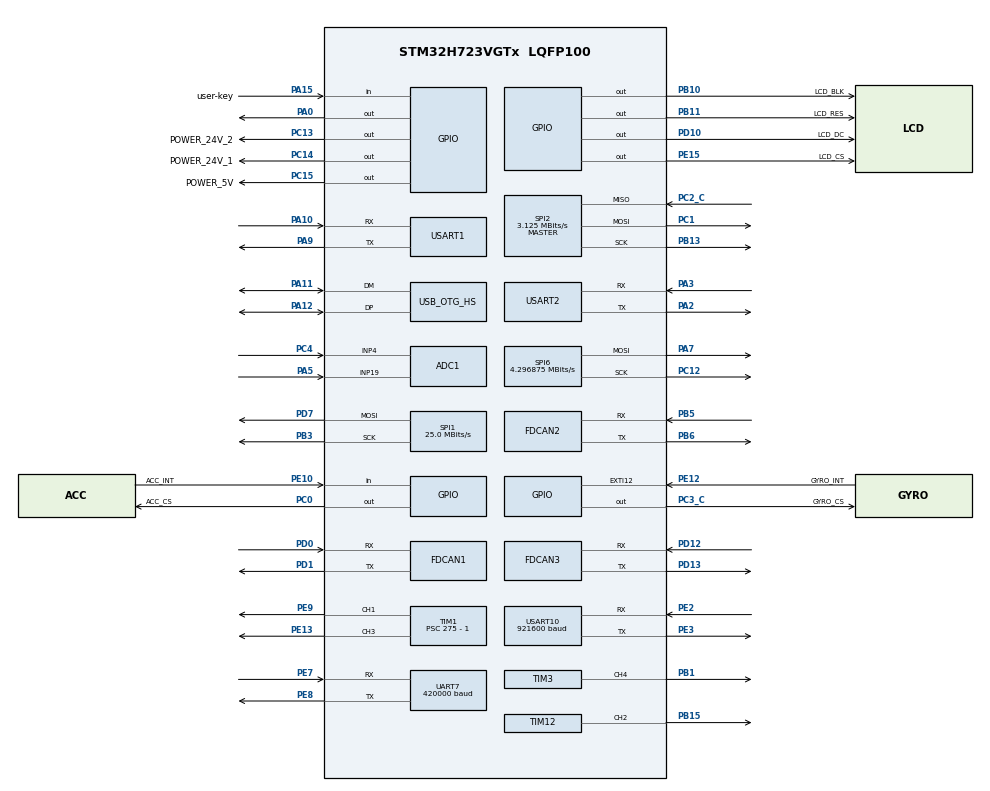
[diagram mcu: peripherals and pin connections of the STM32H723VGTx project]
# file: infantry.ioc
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ADC1.Channel-0\#ChannelRegularConversion=ADC_CHANNEL_4
ADC1.Channel-1\#ChannelRegularConversion=ADC_CHANNEL_19
ADC1.ClockPrescaler=ADC_CLOCK_ASYNC_DIV64
ADC1.ContinuousConvMode=ENABLE
ADC1.ConversionDataManagement=ADC_CONVERSIONDATA_DMA_CIRCULAR
ADC1.NbrOfConversion=2
ADC1.NbrOfConversionFlag=1
ADC1.OffsetNumber-0\#ChannelRegularConversion=ADC_OFFSET_NONE
ADC1.OffsetNumber-1\#ChannelRegularConversion=ADC_OFFSET_NONE
ADC1.OffsetSignedSaturation-0\#ChannelRegularConversion=DISABLE
ADC1.OffsetSignedSaturation-1\#ChannelRegularConversion=DISABLE
ADC1.Rank-0\#ChannelRegularConversion=1
ADC1.Rank-1\#ChannelRegularConversion=2
ADC1.Ratio=1
ADC1.SamplingTime-0\#ChannelRegularConversion=ADC_SAMPLETIME_32CYCLES_5
ADC1.SamplingTime-1\#ChannelRegularConversion=ADC_SAMPLETIME_32CYCLES_5
ADC1.master=1
CORTEX_M7.AccessPermission_Spec=MPU_REGION_FULL_ACCESS
CORTEX_M7.BaseAddress_Spec=0x24000000
CORTEX_M7.CPU_DCache=Enabled
CORTEX_M7.CPU_ICache=Enabled
CORTEX_M7.DisableExec_Spec=MPU_INSTRUCTION_ACCESS_ENABLE
CORTEX_M7.IsBufferable_Spec=MPU_ACCESS_NOT_BUFFERABLE
CORTEX_M7.IsCacheable_Spec=MPU_ACCESS_NOT_CACHEABLE
CORTEX_M7.IsShareable_Spec=MPU_ACCESS_NOT_SHAREABLE
CORTEX_M7.MPU_Control=MPU_HFNMI_PRIVDEF
CORTEX_M7.Size_Spec=MPU_REGION_SIZE_512KB
CORTEX_M7.SubRegionDisable_Spec=0x0
CORTEX_M7.TypeExtField_Spec=MPU_TEX_LEVEL1
CORTEX_M7.default_mode_Activation=1
Dma.ADC1.8.Direction=DMA_PERIPH_TO_MEMORY
Dma.ADC1.8.EventEnable=DISABLE
Dma.ADC1.8.FIFOMode=DMA_FIFOMODE_DISABLE
Dma.ADC1.8.Instance=DMA2_Stream0
Dma.ADC1.8.MemDataAlignment=DMA_MDATAALIGN_HALFWORD
Dma.ADC1.8.MemInc=DMA_MINC_ENABLE
Dma.ADC1.8.Mode=DMA_CIRCULAR
Dma.ADC1.8.PeriphDataAlignment=DMA_PDATAALIGN_HALFWORD
Dma.ADC1.8.PeriphInc=DMA_PINC_DISABLE
Dma.ADC1.8.Polarity=HAL_DMAMUX_REQ_GEN_RISING
Dma.ADC1.8.Priority=DMA_PRIORITY_LOW
Dma.ADC1.8.RequestNumber=1
Dma.ADC1.8.SignalID=NONE
Dma.ADC1.8.SyncEnable=DISABLE
Dma.ADC1.8.SyncPolarity=HAL_DMAMUX_SYNC_NO_EVENT
Dma.ADC1.8.SyncRequestNumber=1
Dma.ADC1.8.SyncSignalID=NONE
Dma.Request0=SPI2_RX
Dma.Request1=SPI2_TX
Dma.Request10=USART1_TX
Dma.Request2=USART2_RX
Dma.Request3=USART2_TX
Dma.Request4=USART10_RX
Dma.Request5=USART10_TX
Dma.Request6=UART7_RX
Dma.Request7=UART7_TX
Dma.Request8=ADC1
Dma.Request9=USART1_RX
Dma.SPI2_RX.0.Direction=DMA_PERIPH_TO_MEMORY
Dma.SPI2_RX.0.EventEnable=DISABLE
Dma.SPI2_RX.0.FIFOMode=DMA_FIFOMODE_DISABLE
Dma.SPI2_RX.0.Instance=DMA1_Stream0
Dma.SPI2_RX.0.MemDataAlignment=DMA_MDATAALIGN_BYTE
Dma.SPI2_RX.0.MemInc=DMA_MINC_ENABLE
Dma.SPI2_RX.0.Mode=DMA_NORMAL
Dma.SPI2_RX.0.PeriphDataAlignment=DMA_PDATAALIGN_BYTE
Dma.SPI2_RX.0.PeriphInc=DMA_PINC_DISABLE
Dma.SPI2_RX.0.Polarity=HAL_DMAMUX_REQ_GEN_RISING
Dma.SPI2_RX.0.Priority=DMA_PRIORITY_VERY_HIGH
Dma.SPI2_RX.0.RequestNumber=1
Dma.SPI2_RX.0.SignalID=NONE
Dma.SPI2_RX.0.SyncEnable=DISABLE
Dma.SPI2_RX.0.SyncPolarity=HAL_DMAMUX_SYNC_NO_EVENT
Dma.SPI2_RX.0.SyncRequestNumber=1
Dma.SPI2_RX.0.SyncSignalID=NONE
Dma.SPI2_TX.1.Direction=DMA_MEMORY_TO_PERIPH
Dma.SPI2_TX.1.EventEnable=DISABLE
Dma.SPI2_TX.1.FIFOMode=DMA_FIFOMODE_DISABLE
Dma.SPI2_TX.1.Instance=DMA1_Stream1
Dma.SPI2_TX.1.MemDataAlignment=DMA_MDATAALIGN_BYTE
Dma.SPI2_TX.1.MemInc=DMA_MINC_ENABLE
Dma.SPI2_TX.1.Mode=DMA_NORMAL
Dma.SPI2_TX.1.PeriphDataAlignment=DMA_PDATAALIGN_BYTE
Dma.SPI2_TX.1.PeriphInc=DMA_PINC_DISABLE
Dma.SPI2_TX.1.Polarity=HAL_DMAMUX_REQ_GEN_RISING
Dma.SPI2_TX.1.Priority=DMA_PRIORITY_HIGH
Dma.SPI2_TX.1.RequestNumber=1
Dma.SPI2_TX.1.SignalID=NONE
Dma.SPI2_TX.1.SyncEnable=DISABLE
Dma.SPI2_TX.1.SyncPolarity=HAL_DMAMUX_SYNC_NO_EVENT
Dma.SPI2_TX.1.SyncRequestNumber=1
Dma.SPI2_TX.1.SyncSignalID=NONE
Dma.UART7_RX.6.Direction=DMA_PERIPH_TO_MEMORY
Dma.UART7_RX.6.EventEnable=DISABLE
Dma.UART7_RX.6.FIFOMode=DMA_FIFOMODE_DISABLE
Dma.UART7_RX.6.Instance=DMA1_Stream4
Dma.UART7_RX.6.MemDataAlignment=DMA_MDATAALIGN_BYTE
Dma.UART7_RX.6.MemInc=DMA_MINC_ENABLE
Dma.UART7_RX.6.Mode=DMA_NORMAL
Dma.UART7_RX.6.PeriphDataAlignment=DMA_PDATAALIGN_BYTE
Dma.UART7_RX.6.PeriphInc=DMA_PINC_DISABLE
Dma.UART7_RX.6.Polarity=HAL_DMAMUX_REQ_GEN_RISING
Dma.UART7_RX.6.Priority=DMA_PRIORITY_VERY_HIGH
Dma.UART7_RX.6.RequestNumber=1
Dma.UART7_RX.6.SignalID=NONE
Dma.UART7_RX.6.SyncEnable=DISABLE
Dma.UART7_RX.6.SyncPolarity=HAL_DMAMUX_SYNC_NO_EVENT
Dma.UART7_RX.6.SyncRequestNumber=1
Dma.UART7_RX.6.SyncSignalID=NONE
Dma.UART7_TX.7.Direction=DMA_MEMORY_TO_PERIPH
Dma.UART7_TX.7.EventEnable=DISABLE
Dma.UART7_TX.7.FIFOMode=DMA_FIFOMODE_DISABLE
Dma.UART7_TX.7.Instance=DMA1_Stream5
Dma.UART7_TX.7.MemDataAlignment=DMA_MDATAALIGN_BYTE
Dma.UART7_TX.7.MemInc=DMA_MINC_ENABLE
Dma.UART7_TX.7.Mode=DMA_NORMAL
Dma.UART7_TX.7.PeriphDataAlignment=DMA_PDATAALIGN_BYTE
Dma.UART7_TX.7.PeriphInc=DMA_PINC_DISABLE
Dma.UART7_TX.7.Polarity=HAL_DMAMUX_REQ_GEN_RISING
Dma.UART7_TX.7.Priority=DMA_PRIORITY_LOW
Dma.UART7_TX.7.RequestNumber=1
Dma.UART7_TX.7.SignalID=NONE
Dma.UART7_TX.7.SyncEnable=DISABLE
Dma.UART7_TX.7.SyncPolarity=HAL_DMAMUX_SYNC_NO_EVENT
Dma.UART7_TX.7.SyncRequestNumber=1
Dma.UART7_TX.7.SyncSignalID=NONE
Dma.USART10_RX.4.Direction=DMA_PERIPH_TO_MEMORY
Dma.USART10_RX.4.EventEnable=DISABLE
Dma.USART10_RX.4.FIFOMode=DMA_FIFOMODE_DISABLE
Dma.USART10_RX.4.Instance=DMA1_Stream6
Dma.USART10_RX.4.MemDataAlignment=DMA_MDATAALIGN_BYTE
Dma.USART10_RX.4.MemInc=DMA_MINC_ENABLE
Dma.USART10_RX.4.Mode=DMA_NORMAL
Dma.USART10_RX.4.PeriphDataAlignment=DMA_PDATAALIGN_BYTE
Dma.USART10_RX.4.PeriphInc=DMA_PINC_DISABLE
Dma.USART10_RX.4.Polarity=HAL_DMAMUX_REQ_GEN_RISING
Dma.USART10_RX.4.Priority=DMA_PRIORITY_HIGH
Dma.USART10_RX.4.RequestNumber=1
Dma.USART10_RX.4.SignalID=NONE
Dma.USART10_RX.4.SyncEnable=DISABLE
Dma.USART10_RX.4.SyncPolarity=HAL_DMAMUX_SYNC_NO_EVENT
Dma.USART10_RX.4.SyncRequestNumber=1
Dma.USART10_RX.4.SyncSignalID=NONE
Dma.USART10_TX.5.Direction=DMA_MEMORY_TO_PERIPH
Dma.USART10_TX.5.EventEnable=DISABLE
Dma.USART10_TX.5.FIFOMode=DMA_FIFOMODE_DISABLE
Dma.USART10_TX.5.Instance=DMA1_Stream7
Dma.USART10_TX.5.MemDataAlignment=DMA_MDATAALIGN_BYTE
Dma.USART10_TX.5.MemInc=DMA_MINC_ENABLE
Dma.USART10_TX.5.Mode=DMA_NORMAL
Dma.USART10_TX.5.PeriphDataAlignment=DMA_PDATAALIGN_BYTE
Dma.USART10_TX.5.PeriphInc=DMA_PINC_DISABLE
Dma.USART10_TX.5.Polarity=HAL_DMAMUX_REQ_GEN_RISING
Dma.USART10_TX.5.Priority=DMA_PRIORITY_HIGH
Dma.USART10_TX.5.RequestNumber=1
Dma.USART10_TX.5.SignalID=NONE
Dma.USART10_TX.5.SyncEnable=DISABLE
Dma.USART10_TX.5.SyncPolarity=HAL_DMAMUX_SYNC_NO_EVENT
Dma.USART10_TX.5.SyncRequestNumber=1
Dma.USART10_TX.5.SyncSignalID=NONE
Dma.USART1_RX.9.Direction=DMA_PERIPH_TO_MEMORY
Dma.USART1_RX.9.EventEnable=DISABLE
Dma.USART1_RX.9.FIFOMode=DMA_FIFOMODE_DISABLE
Dma.USART1_RX.9.Instance=DMA2_Stream1
Dma.USART1_RX.9.MemDataAlignment=DMA_MDATAALIGN_BYTE
Dma.USART1_RX.9.MemInc=DMA_MINC_ENABLE
Dma.USART1_RX.9.Mode=DMA_NORMAL
Dma.USART1_RX.9.PeriphDataAlignment=DMA_PDATAALIGN_BYTE
Dma.USART1_RX.9.PeriphInc=DMA_PINC_DISABLE
Dma.USART1_RX.9.Polarity=HAL_DMAMUX_REQ_GEN_RISING
Dma.USART1_RX.9.Priority=DMA_PRIORITY_LOW
Dma.USART1_RX.9.RequestNumber=1
Dma.USART1_RX.9.SignalID=NONE
Dma.USART1_RX.9.SyncEnable=DISABLE
Dma.USART1_RX.9.SyncPolarity=HAL_DMAMUX_SYNC_NO_EVENT
Dma.USART1_RX.9.SyncRequestNumber=1
Dma.USART1_RX.9.SyncSignalID=NONE
Dma.USART1_TX.10.Direction=DMA_MEMORY_TO_PERIPH
Dma.USART1_TX.10.EventEnable=DISABLE
Dma.USART1_TX.10.FIFOMode=DMA_FIFOMODE_DISABLE
Dma.USART1_TX.10.Instance=DMA2_Stream2
Dma.USART1_TX.10.MemDataAlignment=DMA_MDATAALIGN_BYTE
Dma.USART1_TX.10.MemInc=DMA_MINC_ENABLE
Dma.USART1_TX.10.Mode=DMA_NORMAL
Dma.USART1_TX.10.PeriphDataAlignment=DMA_PDATAALIGN_BYTE
Dma.USART1_TX.10.PeriphInc=DMA_PINC_DISABLE
Dma.USART1_TX.10.Polarity=HAL_DMAMUX_REQ_GEN_RISING
Dma.USART1_TX.10.Priority=DMA_PRIORITY_HIGH
Dma.USART1_TX.10.RequestNumber=1
Dma.USART1_TX.10.SignalID=NONE
Dma.USART1_TX.10.SyncEnable=DISABLE
Dma.USART1_TX.10.SyncPolarity=HAL_DMAMUX_SYNC_NO_EVENT
Dma.USART1_TX.10.SyncRequestNumber=1
Dma.USART1_TX.10.SyncSignalID=NONE
Dma.USART2_RX.2.Direction=DMA_PERIPH_TO_MEMORY
Dma.USART2_RX.2.EventEnable=DISABLE
Dma.USART2_RX.2.FIFOMode=DMA_FIFOMODE_DISABLE
Dma.USART2_RX.2.Instance=DMA1_Stream2
Dma.USART2_RX.2.MemDataAlignment=DMA_MDATAALIGN_BYTE
Dma.USART2_RX.2.MemInc=DMA_MINC_ENABLE
Dma.USART2_RX.2.Mode=DMA_NORMAL
Dma.USART2_RX.2.PeriphDataAlignment=DMA_PDATAALIGN_BYTE
Dma.USART2_RX.2.PeriphInc=DMA_PINC_DISABLE
Dma.USART2_RX.2.Polarity=HAL_DMAMUX_REQ_GEN_RISING
Dma.USART2_RX.2.Priority=DMA_PRIORITY_LOW
Dma.USART2_RX.2.RequestNumber=1
Dma.USART2_RX.2.SignalID=NONE
Dma.USART2_RX.2.SyncEnable=DISABLE
Dma.USART2_RX.2.SyncPolarity=HAL_DMAMUX_SYNC_NO_EVENT
Dma.USART2_RX.2.SyncRequestNumber=1
Dma.USART2_RX.2.SyncSignalID=NONE
Dma.USART2_TX.3.Direction=DMA_MEMORY_TO_PERIPH
Dma.USART2_TX.3.EventEnable=DISABLE
Dma.USART2_TX.3.FIFOMode=DMA_FIFOMODE_DISABLE
Dma.USART2_TX.3.Instance=DMA1_Stream3
Dma.USART2_TX.3.MemDataAlignment=DMA_MDATAALIGN_BYTE
Dma.USART2_TX.3.MemInc=DMA_MINC_ENABLE
Dma.USART2_TX.3.Mode=DMA_NORMAL
Dma.USART2_TX.3.PeriphDataAlignment=DMA_PDATAALIGN_BYTE
Dma.USART2_TX.3.PeriphInc=DMA_PINC_DISABLE
Dma.USART2_TX.3.Polarity=HAL_DMAMUX_REQ_GEN_RISING
Dma.USART2_TX.3.Priority=DMA_PRIORITY_LOW
Dma.USART2_TX.3.RequestNumber=1
Dma.USART2_TX.3.SignalID=NONE
Dma.USART2_TX.3.SyncEnable=DISABLE
Dma.USART2_TX.3.SyncPolarity=HAL_DMAMUX_SYNC_NO_EVENT
Dma.USART2_TX.3.SyncRequestNumber=1
Dma.USART2_TX.3.SyncSignalID=NONE
FDCAN1.AutoRetransmission=ENABLE
FDCAN1.CalculateBaudRateNominal=1000000
FDCAN1.CalculateTimeBitNominal=1000
FDCAN1.CalculateTimeQuantumNominal=50.0
FDCAN1.DataPrescaler=5
FDCAN1.DataSyncJumpWidth=5
FDCAN1.DataTimeSeg1=14
FDCAN1.DataTimeSeg2=5
FDCAN1.NominalPrescaler=5
FDCAN1.NominalSyncJumpWidth=5
FDCAN1.NominalTimeSeg1=14
FDCAN1.NominalTimeSeg2=5
FDCAN1.ProtocolException=ENABLE
FDCAN1.RxFifo0ElmtsNbr=8
FDCAN1.StdFiltersNbr=1
FDCAN1.TxFifoQueueElmtsNbr=8
FDCAN2.AutoRetransmission=ENABLE
FDCAN2.CalculateBaudRateNominal=1000000
FDCAN2.CalculateTimeBitNominal=1000
FDCAN2.CalculateTimeQuantumNominal=50.0
FDCAN2.DataSyncJumpWidth=5
FDCAN2.DataTimeSeg1=14
FDCAN2.DataTimeSeg2=5
FDCAN2.MessageRAMOffset=853
FDCAN2.NominalPrescaler=5
FDCAN2.NominalSyncJumpWidth=5
FDCAN2.NominalTimeSeg1=14
FDCAN2.NominalTimeSeg2=5
FDCAN2.ProtocolException=ENABLE
FDCAN2.RxFifo1ElmtsNbr=8
FDCAN2.StdFiltersNbr=1
FDCAN2.TxFifoQueueElmtsNbr=8
FDCAN3.AutoRetransmission=ENABLE
FDCAN3.CalculateBaudRateNominal=1000000
FDCAN3.CalculateTimeBitNominal=1000
FDCAN3.CalculateTimeQuantumNominal=50.0
FDCAN3.DataPrescaler=5
FDCAN3.DataSyncJumpWidth=5
FDCAN3.DataTimeSeg1=14
FDCAN3.DataTimeSeg2=5
FDCAN3.MessageRAMOffset=1706
FDCAN3.NominalPrescaler=5
FDCAN3.NominalSyncJumpWidth=5
FDCAN3.NominalTimeSeg1=14
FDCAN3.NominalTimeSeg2=5
FDCAN3.ProtocolException=ENABLE
FDCAN3.RxFifo0ElmtsNbr=8
FDCAN3.StdFiltersNbr=1
FDCAN3.TxFifoQueueElmtsNbr=8
FREERTOS.Tasks01=defaultTask,24,256,StartDefaultTask,Default,NULL,Static,defaultTaskBuffer,defaultTaskControlBlock;test,8,128,test_task,As weak,NULL,Static,testBuffer,testControlBlock;remote_control,24,512,remote_control_task,As weak,NULL,Static,remote_controlBuffer,remote_controlControlBlock;decision_center,24,1024,decision_center_task,As weak,NULL,Static,decision_centerBuffer,decision_centerControlBlock;safe_daemon,24,256,safe_daemon_task,As weak,NULL,Static,safe_daemonBuffer,safe_daemonControlBlock;ins_task_rtos,40,1024,imu_task,As weak,NULL,Static,ins_task_rtosBuffer,ins_task_rtosControlBlock;chassis,24,1024,chassis_task,As weak,NULL,Static,chassisBuffer,chassisControlBlock
FREERTOS.configCHECK_FOR_STACK_OVERFLOW=0
FREERTOS.configENABLE_FPU=1
FREERTOS.configTOTAL_HEAP_SIZE=15360
Mcu.Family=STM32H7
Mcu.Name=STM32H723VGTx
Mcu.Package=LQFP100
NVIC.DMA1_Stream0_IRQn=true\:5\:0\:false\:false\:true\:true\:false\:true\:true
NVIC.DMA1_Stream1_IRQn=true\:5\:0\:false\:false\:true\:true\:false\:true\:true
NVIC.DMA1_Stream2_IRQn=true\:5\:0\:false\:false\:true\:true\:false\:true\:true
NVIC.DMA1_Stream3_IRQn=true\:5\:0\:false\:false\:true\:true\:false\:true\:true
NVIC.DMA1_Stream4_IRQn=true\:5\:0\:false\:false\:true\:true\:false\:true\:true
NVIC.DMA1_Stream5_IRQn=true\:5\:0\:false\:false\:true\:true\:false\:true\:true
NVIC.DMA1_Stream6_IRQn=true\:5\:0\:false\:false\:true\:true\:false\:true\:true
NVIC.DMA1_Stream7_IRQn=true\:5\:0\:false\:false\:true\:true\:false\:true\:true
NVIC.DMA2_Stream0_IRQn=true\:5\:0\:false\:false\:true\:true\:false\:true\:true
NVIC.DMA2_Stream1_IRQn=true\:5\:0\:false\:false\:true\:true\:false\:true\:true
NVIC.DMA2_Stream2_IRQn=true\:5\:0\:false\:false\:true\:true\:false\:true\:true
NVIC.EXTI15_10_IRQn=true\:5\:0\:false\:false\:true\:true\:true\:true\:true
NVIC.FDCAN1_IT0_IRQn=true\:5\:0\:false\:false\:true\:true\:true\:true\:true
NVIC.FDCAN1_IT1_IRQn=true\:5\:0\:false\:false\:true\:true\:true\:true\:true
NVIC.FDCAN2_IT0_IRQn=true\:5\:0\:false\:false\:true\:true\:true\:true\:true
NVIC.FDCAN2_IT1_IRQn=true\:5\:0\:false\:false\:true\:true\:true\:true\:true
NVIC.FDCAN3_IT0_IRQn=true\:5\:0\:false\:false\:true\:true\:true\:true\:true
NVIC.FDCAN3_IT1_IRQn=true\:5\:0\:false\:false\:true\:true\:true\:true\:true
NVIC.OTG_HS_IRQn=true\:5\:0\:false\:false\:true\:true\:true\:true\:true
NVIC.PriorityGroup=NVIC_PRIORITYGROUP_4
NVIC.SPI2_IRQn=true\:5\:0\:false\:false\:true\:true\:false\:true\:true
NVIC.TIM2_IRQn=true\:15\:0\:false\:false\:true\:false\:false\:true\:true
NVIC.TimeBase=TIM2_IRQn
NVIC.TimeBaseIP=TIM2
NVIC.UART7_IRQn=true\:5\:0\:false\:false\:true\:true\:true\:true\:true
NVIC.USART10_IRQn=true\:5\:0\:false\:false\:true\:true\:true\:true\:true
NVIC.USART1_IRQn=true\:5\:0\:false\:false\:true\:true\:true\:true\:true
NVIC.USART2_IRQn=true\:5\:0\:false\:false\:true\:true\:true\:true\:true
PA0.GPIO_Speed=GPIO_SPEED_FREQ_VERY_HIGH
PA0.Signal=GPIO_Output
PA10.Mode=Asynchronous
PA10.Signal=USART1_RX
PA11.Mode=Device_Only_FS
PA11.Signal=USB_OTG_HS_DM
PA12.Mode=Device_Only_FS
PA12.Signal=USB_OTG_HS_DP
PA13(JTMS/SWDIO).Mode=Serial_Wire
PA13(JTMS/SWDIO).Signal=DEBUG_JTMS-SWDIO
PA14(JTCK/SWCLK).Mode=Serial_Wire
PA14(JTCK/SWCLK).Signal=DEBUG_JTCK-SWCLK
PA15(JTDI).GPIO_Label=user-key
PA15(JTDI).GPIO_PuPd=GPIO_PULLUP
PA15(JTDI).Signal=GPIO_Input
PA2.Mode=Asynchronous
PA2.Signal=USART2_TX
PA3.Mode=Asynchronous
PA3.Signal=USART2_RX
PA5.Signal=ADCx_INP19
PA7.GPIO_Speed=GPIO_SPEED_FREQ_VERY_HIGH
PA7.Mode=TX_Only_Simplex_Unidirect_Master
PA7.Signal=SPI6_MOSI
PA9.Mode=Asynchronous
PA9.Signal=USART1_TX
PB1.Signal=S_TIM3_CH4
PB10.GPIO_Label=LCD_BLK
PB10.Signal=GPIO_Output
PB11.GPIO_Label=LCD_RES
PB11.Signal=GPIO_Output
PB13.GPIO_Speed=GPIO_SPEED_FREQ_VERY_HIGH
PB13.Mode=Full_Duplex_Master
PB13.Signal=SPI2_SCK
PB15.Signal=S_TIM12_CH2
PB3(JTDO/TRACESWO).Mode=TX_Only_Simplex_Unidirect_Master
PB3(JTDO/TRACESWO).Signal=SPI1_SCK
PB5.Mode=FDCAN_Activate
PB5.Signal=FDCAN2_RX
PB6.Mode=FDCAN_Activate
PB6.Signal=FDCAN2_TX
PC0.GPIO_Label=ACC_CS
PC0.GPIO_Speed=GPIO_SPEED_FREQ_VERY_HIGH
PC0.PinState=GPIO_PIN_SET
PC0.Signal=GPIO_Output
PC1.GPIO_Speed=GPIO_SPEED_FREQ_VERY_HIGH
PC1.Mode=Full_Duplex_Master
PC1.Signal=SPI2_MOSI
PC12.GPIO_Speed=GPIO_SPEED_FREQ_VERY_HIGH
PC12.Mode=TX_Only_Simplex_Unidirect_Master
PC12.Signal=SPI6_SCK
PC13.GPIO_Label=POWER_24V_2
PC13.PinState=GPIO_PIN_SET
PC13.Signal=GPIO_Output
PC14-OSC32_IN.GPIO_Label=POWER_24V_1
PC14-OSC32_IN.PinState=GPIO_PIN_SET
PC14-OSC32_IN.Signal=GPIO_Output
PC15-OSC32_OUT.GPIO_Label=POWER_5V
PC15-OSC32_OUT.PinState=GPIO_PIN_SET
PC15-OSC32_OUT.Signal=GPIO_Output
PC2_C.GPIO_Speed=GPIO_SPEED_FREQ_VERY_HIGH
PC2_C.Mode=Full_Duplex_Master
PC2_C.Signal=SPI2_MISO
PC3_C.GPIO_Label=GYRO_CS
PC3_C.GPIO_Speed=GPIO_SPEED_FREQ_VERY_HIGH
PC3_C.PinState=GPIO_PIN_SET
PC3_C.Signal=GPIO_Output
PC4.Signal=ADCx_INP4
PD0.Mode=FDCAN_Activate
PD0.Signal=FDCAN1_RX
PD1.Mode=FDCAN_Activate
PD1.Signal=FDCAN1_TX
PD10.GPIO_Label=LCD_DC
PD10.Signal=GPIO_Output
PD12.Mode=FDCAN_Activate
PD12.Signal=FDCAN3_RX
PD13.Mode=FDCAN_Activate
PD13.Signal=FDCAN3_TX
PD7.Mode=TX_Only_Simplex_Unidirect_Master
PD7.Signal=SPI1_MOSI
PE10.GPIO_Label=ACC_INT
PE10.Signal=GPIO_Input
PE12.GPIO_Label=GYRO_INT
PE12.GPIO_ModeDefaultEXTI=GPIO_MODE_IT_FALLING
PE12.Signal=GPXTI12
PE13.Signal=S_TIM1_CH3
PE15.GPIO_Label=LCD_CS
PE15.Signal=GPIO_Output
PE2.GPIO_Speed=GPIO_SPEED_FREQ_LOW
PE2.Mode=Asynchronous
PE2.Signal=USART10_RX
PE3.GPIO_Speed=GPIO_SPEED_FREQ_LOW
PE3.Mode=Asynchronous
PE3.Signal=USART10_TX
PE7.Mode=Asynchronous
PE7.Signal=UART7_RX
PE8.Mode=Asynchronous
PE8.Signal=UART7_TX
PE9.Signal=S_TIM1_CH1
PH0-OSC_IN.Mode=HSE-External-Oscillator
PH0-OSC_IN.Signal=RCC_OSC_IN
PH1-OSC_OUT.Mode=HSE-External-Oscillator
PH1-OSC_OUT.Signal=RCC_OSC_OUT
ProjectManager.HeapSize=0x1000
ProjectManager.StackSize=0x2000
ProjectManager.TargetToolchain=CMake
RCC.ADCFreq_Value=100000000
RCC.APB1Freq_Value=137500000
RCC.APB2Freq_Value=137500000
RCC.APB3Freq_Value=137500000
RCC.APB4Freq_Value=137500000
RCC.CortexFreq_Value=550000000
RCC.D1PPRE=RCC_APB3_DIV2
RCC.D2PPRE1=RCC_APB1_DIV2
RCC.D2PPRE2=RCC_APB2_DIV2
RCC.D3PPRE=RCC_APB4_DIV2
RCC.DIVM1=3
RCC.DIVM2=24
RCC.DIVM3=24
RCC.DIVN1=68
RCC.DIVN2=200
RCC.DIVN3=160
RCC.DIVP1=1
RCC.DIVQ1=4
RCC.FDCANCLockSelection=RCC_FDCANCLKSOURCE_PLL2
RCC.HCLKFreq_Value=275000000
RCC.HPRE=RCC_HCLK_DIV2
RCC.HSE_VALUE=24000000
RCC.PLLFRACN=6144
RCC.PLLSourceVirtual=RCC_PLLSOURCE_HSE
RCC.SPI123CLockSelection=RCC_SPI123CLKSOURCE_PLL2
RCC.SYSCLKFreq_VALUE=550000000
RCC.SYSCLKSource=RCC_SYSCLKSOURCE_PLLCLK
RCC.USBCLockSelection=RCC_USBCLKSOURCE_HSI48
RCC.USBFreq_Value=48000000
SH.ADCx_INP19.0=ADC1_INP19,IN19-Single-Ended
SH.ADCx_INP4.0=ADC1_INP4,IN4-Single-Ended
SH.S_TIM12_CH2.0=TIM12_CH2,PWM Generation2 CH2
SH.S_TIM1_CH1.0=TIM1_CH1,PWM Generation1 CH1
SH.S_TIM1_CH3.0=TIM1_CH3,PWM Generation3 CH3
SH.S_TIM3_CH4.0=TIM3_CH4,PWM Generation4 CH4
SPI1.BaudRatePrescaler=SPI_BAUDRATEPRESCALER_4
SPI1.CLKPolarity=SPI_POLARITY_HIGH
SPI1.CalculateBaudRate=25.0 MBits/s
SPI1.DataSize=SPI_DATASIZE_8BIT
SPI1.Direction=SPI_DIRECTION_2LINES_TXONLY
SPI1.Mode=SPI_MODE_MASTER
SPI1.VirtualType=VM_MASTER
SPI2.BaudRatePrescaler=SPI_BAUDRATEPRESCALER_32
SPI2.CLKPhase=SPI_PHASE_2EDGE
SPI2.CLKPolarity=SPI_POLARITY_HIGH
SPI2.CalculateBaudRate=3.125 MBits/s
SPI2.DataSize=SPI_DATASIZE_8BIT
SPI2.Direction=SPI_DIRECTION_2LINES
SPI2.Mode=SPI_MODE_MASTER
SPI2.VirtualType=VM_MASTER
SPI6.BaudRatePrescaler=SPI_BAUDRATEPRESCALER_32
SPI6.CLKPhase=SPI_PHASE_2EDGE
SPI6.CalculateBaudRate=4.296875 MBits/s
SPI6.DataSize=SPI_DATASIZE_8BIT
SPI6.Direction=SPI_DIRECTION_2LINES_TXONLY
SPI6.Mode=SPI_MODE_MASTER
SPI6.VirtualType=VM_MASTER
TIM1.Channel-PWM\ Generation1\ CH1=TIM_CHANNEL_1
TIM1.Channel-PWM\ Generation3\ CH3=TIM_CHANNEL_3
TIM1.Period=20000 - 1
TIM1.Prescaler=275 - 1
TIM12.Channel-PWM\ Generation2\ CH2=TIM_CHANNEL_2
TIM12.OC2Preload_PWM=DISABLE
TIM12.Period=250-1
TIM12.Prescaler=275-1
TIM3.AutoReloadPreload=TIM_AUTORELOAD_PRELOAD_ENABLE
TIM3.Channel-PWM\ Generation4\ CH4=TIM_CHANNEL_4
TIM3.Period=10000-1
TIM3.Prescaler=1-1
UART7.BaudRate=420000
USART1.VirtualMode-Asynchronous=VM_ASYNC
USART10.BaudRate=921600
USART10.VirtualMode=VM_ASYNC
USART2.VirtualMode-Asynchronous=VM_ASYNC
USB_DEVICE.CLASS_NAME_HS=CDC
USB_DEVICE.VirtualMode=Cdc
USB_DEVICE.VirtualModeHS=Cdc_HS
USB_OTG_HS.VirtualMode-Device_Only_FS=Device_Only_FS
VP_FREERTOS_VS_CMSIS_V2.Mode=CMSIS_V2
VP_MEMORYMAP_VS_MEMORYMAP.Mode=CurAppReg
VP_SYS_VS_tim2.Mode=TIM2
VP_USB_DEVICE_VS_USB_DEVICE_CDC_HS.Mode=CDC_HS
board=custom

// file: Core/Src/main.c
/* USER CODE BEGIN Header */
/**
  ******************************************************************************
  * @file           : main.c
  * @brief          : Main program body
  ******************************************************************************
  * @attention
  *
  * Copyright (c) 2026 STMicroelectronics.
  * All rights reserved.
  *
  * This software is licensed under terms that can be found in the LICENSE file
  * in the root directory of this software component.
  * If no LICENSE file comes with this software, it is provided AS-IS.
  *
  ******************************************************************************
  */
/* USER CODE END Header */
#include "main.h"
#include "cmsis_os.h"
#include "adc.h"
#include "dma.h"
#include "fdcan.h"
#include "spi.h"
#include "tim.h"
#include "usart.h"
#include "usb_device.h"
#include "gpio.h"

/* USER CODE BEGIN Includes */
#include "bsp_mcu.h"
/* USER CODE END Includes */

void SystemClock_Config(void);
void PeriphCommonClock_Config(void);
static void MPU_Config(void);
void MX_FREERTOS_Init(void);

int main(void)
{

  /* MPU Configuration--------------------------------------------------------*/
  MPU_Config();

  /* Enable the CPU Cache */

  /* Enable I-Cache---------------------------------------------------------*/
  SCB_EnableICache();

  /* Enable D-Cache---------------------------------------------------------*/
  SCB_EnableDCache();

  /* MCU Configuration--------------------------------------------------------*/

  /* Reset of all peripherals, Initializes the Flash interface and the Systick. */
  HAL_Init();

  /* Configure the system clock */
  SystemClock_Config();

  /* Configure the peripherals common clocks */
  PeriphCommonClock_Config();

  /* Initialize all configured peripherals */
  MX_GPIO_Init();
  MX_DMA_Init();
  MX_SPI2_Init();
  MX_TIM3_Init();
  MX_USART2_UART_Init();
  MX_FDCAN1_Init();
  MX_FDCAN2_Init();
  MX_FDCAN3_Init();
  MX_TIM12_Init();
  MX_USART10_UART_Init();
  MX_UART7_Init();
  MX_ADC1_Init();
  MX_SPI6_Init();
  MX_SPI1_Init();
  MX_TIM1_Init();
  MX_USART1_UART_Init();
  /* USER CODE BEGIN 2 */
  bsp_mcu_init();
  /* USER CODE END 2 */

  /* Init scheduler */
  osKernelInitialize();  /* Call init function for freertos objects (in cmsis_os2.c) */
  MX_FREERTOS_Init();

  /* Start scheduler */
  osKernelStart();

  /* We should never get here as control is now taken by the scheduler */

  /* Infinite loop */
  while (1)
  {

  }
}

void SystemClock_Config(void)
{
  RCC_OscInitTypeDef RCC_OscInitStruct = {0};
  RCC_ClkInitTypeDef RCC_ClkInitStruct = {0};

  /** Supply configuration update enable
  */
  HAL_PWREx_ConfigSupply(PWR_LDO_SUPPLY);

  /** Configure the main internal regulator output voltage
  */
  __HAL_PWR_VOLTAGESCALING_CONFIG(PWR_REGULATOR_VOLTAGE_SCALE0);

  while(!__HAL_PWR_GET_FLAG(PWR_FLAG_VOSRDY)) {}

  /** Initializes the RCC Oscillators according to the specified parameters
  * in the RCC_OscInitTypeDef structure.
  */
  RCC_OscInitStruct.OscillatorType = RCC_OSCILLATORTYPE_HSI48|RCC_OSCILLATORTYPE_HSE;
  RCC_OscInitStruct.HSEState = RCC_HSE_ON;
  RCC_OscInitStruct.HSI48State = RCC_HSI48_ON;
  RCC_OscInitStruct.PLL.PLLState = RCC_PLL_ON;
  RCC_OscInitStruct.PLL.PLLSource = RCC_PLLSOURCE_HSE;
  RCC_OscInitStruct.PLL.PLLM = 3;
  RCC_OscInitStruct.PLL.PLLN = 68;
  RCC_OscInitStruct.PLL.PLLP = 1;
  RCC_OscInitStruct.PLL.PLLQ = 4;
  RCC_OscInitStruct.PLL.PLLR = 2;
  RCC_OscInitStruct.PLL.PLLRGE = RCC_PLL1VCIRANGE_3;
  RCC_OscInitStruct.PLL.PLLVCOSEL = RCC_PLL1VCOWIDE;
  RCC_OscInitStruct.PLL.PLLFRACN = 6144;
  if (HAL_RCC_OscConfig(&RCC_OscInitStruct) != HAL_OK)
  {
    Error_Handler();
  }

  /** Initializes the CPU, AHB and APB buses clocks
  */
  RCC_ClkInitStruct.ClockType = RCC_CLOCKTYPE_HCLK|RCC_CLOCKTYPE_SYSCLK
                              |RCC_CLOCKTYPE_PCLK1|RCC_CLOCKTYPE_PCLK2
                              |RCC_CLOCKTYPE_D3PCLK1|RCC_CLOCKTYPE_D1PCLK1;
  RCC_ClkInitStruct.SYSCLKSource = RCC_SYSCLKSOURCE_PLLCLK;
  RCC_ClkInitStruct.SYSCLKDivider = RCC_SYSCLK_DIV1;
  RCC_ClkInitStruct.AHBCLKDivider = RCC_HCLK_DIV2;
  RCC_ClkInitStruct.APB3CLKDivider = RCC_APB3_DIV2;
  RCC_ClkInitStruct.APB1CLKDivider = RCC_APB1_DIV2;
  RCC_ClkInitStruct.APB2CLKDivider = RCC_APB2_DIV2;
  RCC_ClkInitStruct.APB4CLKDivider = RCC_APB4_DIV2;

  if (HAL_RCC_ClockConfig(&RCC_ClkInitStruct, FLASH_LATENCY_3) != HAL_OK)
  {
    Error_Handler();
  }
}

void PeriphCommonClock_Config(void)
{
  RCC_PeriphCLKInitTypeDef PeriphClkInitStruct = {0};

  /** Initializes the peripherals clock
  */
  PeriphClkInitStruct.PeriphClockSelection = RCC_PERIPHCLK_ADC|RCC_PERIPHCLK_SPI2
                              |RCC_PERIPHCLK_SPI1|RCC_PERIPHCLK_FDCAN;
  PeriphClkInitStruct.PLL2.PLL2M = 24;
  PeriphClkInitStruct.PLL2.PLL2N = 200;
  PeriphClkInitStruct.PLL2.PLL2P = 2;
  PeriphClkInitStruct.PLL2.PLL2Q = 2;
  PeriphClkInitStruct.PLL2.PLL2R = 2;
  PeriphClkInitStruct.PLL2.PLL2RGE = RCC_PLL2VCIRANGE_0;
  PeriphClkInitStruct.PLL2.PLL2VCOSEL = RCC_PLL2VCOMEDIUM;
  PeriphClkInitStruct.PLL2.PLL2FRACN = 0;
  PeriphClkInitStruct.Spi123ClockSelection = RCC_SPI123CLKSOURCE_PLL2;
  PeriphClkInitStruct.FdcanClockSelection = RCC_FDCANCLKSOURCE_PLL2;
  PeriphClkInitStruct.AdcClockSelection = RCC_ADCCLKSOURCE_PLL2;
  if (HAL_RCCEx_PeriphCLKConfig(&PeriphClkInitStruct) != HAL_OK)
  {
    Error_Handler();
  }
}

 /* MPU Configuration */

void MPU_Config(void)
{
  MPU_Region_InitTypeDef MPU_InitStruct = {0};

  /* Disables the MPU */
  HAL_MPU_Disable();

  /** Initializes and configures the Region and the memory to be protected
  */
  MPU_InitStruct.Enable = MPU_REGION_ENABLE;
  MPU_InitStruct.Number = MPU_REGION_NUMBER0;
  MPU_InitStruct.BaseAddress = 0x24000000;
  MPU_InitStruct.Size = MPU_REGION_SIZE_512KB;
  MPU_InitStruct.SubRegionDisable = 0x0;
  MPU_InitStruct.TypeExtField = MPU_TEX_LEVEL1;
  MPU_InitStruct.AccessPermission = MPU_REGION_FULL_ACCESS;
  MPU_InitStruct.DisableExec = MPU_INSTRUCTION_ACCESS_ENABLE;
  MPU_InitStruct.IsShareable = MPU_ACCESS_NOT_SHAREABLE;
  MPU_InitStruct.IsCacheable = MPU_ACCESS_NOT_CACHEABLE;
  MPU_InitStruct.IsBufferable = MPU_ACCESS_NOT_BUFFERABLE;

  HAL_MPU_ConfigRegion(&MPU_InitStruct);
  /* Enables the MPU */
  HAL_MPU_Enable(MPU_HFNMI_PRIVDEF);

}

void HAL_TIM_PeriodElapsedCallback(TIM_HandleTypeDef *htim)
{
  if (htim->Instance == TIM2)
  {
    HAL_IncTick();
  }
}

void Error_Handler(void)
{
  __disable_irq();
  while (1)
  {
  }
}

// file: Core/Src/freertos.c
/* USER CODE BEGIN Header */
/**
  ******************************************************************************
  * File Name          : freertos.c
  * Description        : Code for freertos applications
  ******************************************************************************
  * @attention
  *
  * Copyright (c) 2026 STMicroelectronics.
  * All rights reserved.
  *
  * This software is licensed under terms that can be found in the LICENSE file
  * in the root directory of this software component.
  * If no LICENSE file comes with this software, it is provided AS-IS.
  *
  ******************************************************************************
  */
/* USER CODE END Header */

#include "FreeRTOS.h"
#include "task.h"
#include "main.h"
#include "cmsis_os.h"

typedef StaticTask_t osStaticThreadDef_t;

/* USER CODE BEGIN Variables */

/*------------------------------栈溢出现场记录--------------------------------*/
/* configCHECK_FOR_STACK_OVERFLOW = 2 时, 内核在每次上下文切换中比对被换出任务栈尾部的
   填充字(0xA5)是否被破坏, 一旦被覆盖就调用 vApplicationStackOverflowHook(见下方 USER CODE 4).
   这些变量只写不读, 供调试器(Ozone/J-Link)在停机后直接查看定责. */
volatile uint32_t           stack_overflow_count     = 0U;   /* 溢出累计次数 */
volatile TaskHandle_t       stack_overflow_task      = NULL; /* 溢出的任务句柄 */
volatile const char        *stack_overflow_task_name = NULL; /* 溢出的任务名 */
volatile uint32_t           stack_overflow_psp       = 0U;   /* 溢出时任务 PSP, 用于定位越界深度 */

/* USER CODE END Variables */
/* Definitions for defaultTask */
osThreadId_t defaultTaskHandle;
uint32_t defaultTaskBuffer[ 256 ];
osStaticThreadDef_t defaultTaskControlBlock;
const osThreadAttr_t defaultTask_attributes = {
  .name = "defaultTask",
  .cb_mem = &defaultTaskControlBlock,
  .cb_size = sizeof(defaultTaskControlBlock),
  .stack_mem = &defaultTaskBuffer[0],
  .stack_size = sizeof(defaultTaskBuffer),
  .priority = (osPriority_t) osPriorityNormal,
};
/* Definitions for test */
osThreadId_t testHandle;
uint32_t testBuffer[ 128 ];
osStaticThreadDef_t testControlBlock;
const osThreadAttr_t test_attributes = {
  .name = "test",
  .cb_mem = &testControlBlock,
  .cb_size = sizeof(testControlBlock),
  .stack_mem = &testBuffer[0],
  .stack_size = sizeof(testBuffer),
  .priority = (osPriority_t) osPriorityLow,
};
/* Definitions for remote_control */
osThreadId_t remote_controlHandle;
uint32_t remote_controlBuffer[ 512 ];
osStaticThreadDef_t remote_controlControlBlock;
const osThreadAttr_t remote_control_attributes = {
  .name = "remote_control",
  .cb_mem = &remote_controlControlBlock,
  .cb_size = sizeof(remote_controlControlBlock),
  .stack_mem = &remote_controlBuffer[0],
  .stack_size = sizeof(remote_controlBuffer),
  .priority = (osPriority_t) osPriorityNormal,
};
/* Definitions for decision_center */
osThreadId_t decision_centerHandle;
uint32_t decision_centerBuffer[ 1024 ];
osStaticThreadDef_t decision_centerControlBlock;
const osThreadAttr_t decision_center_attributes = {
  .name = "decision_center",
  .cb_mem = &decision_centerControlBlock,
  .cb_size = sizeof(decision_centerControlBlock),
  .stack_mem = &decision_centerBuffer[0],
  .stack_size = sizeof(decision_centerBuffer),
  .priority = (osPriority_t) osPriorityNormal,
};
/* Definitions for safe_daemon */
osThreadId_t safe_daemonHandle;
uint32_t safe_daemonBuffer[ 256 ];
osStaticThreadDef_t safe_daemonControlBlock;
const osThreadAttr_t safe_daemon_attributes = {
  .name = "safe_daemon",
  .cb_mem = &safe_daemonControlBlock,
  .cb_size = sizeof(safe_daemonControlBlock),
  .stack_mem = &safe_daemonBuffer[0],
  .stack_size = sizeof(safe_daemonBuffer),
  .priority = (osPriority_t) osPriorityNormal,
};
/* Definitions for ins_task_rtos */
osThreadId_t ins_task_rtosHandle;
uint32_t ins_task_rtosBuffer[ 1024 ];
osStaticThreadDef_t ins_task_rtosControlBlock;
const osThreadAttr_t ins_task_rtos_attributes = {
  .name = "ins_task_rtos",
  .cb_mem = &ins_task_rtosControlBlock,
  .cb_size = sizeof(ins_task_rtosControlBlock),
  .stack_mem = &ins_task_rtosBuffer[0],
  .stack_size = sizeof(ins_task_rtosBuffer),
  .priority = (osPriority_t) osPriorityHigh,
};
/* Definitions for chassis */
osThreadId_t chassisHandle;
uint32_t chassisBuffer[ 1024 ];
osStaticThreadDef_t chassisControlBlock;
const osThreadAttr_t chassis_attributes = {
  .name = "chassis",
  .cb_mem = &chassisControlBlock,
  .cb_size = sizeof(chassisControlBlock),
  .stack_mem = &chassisBuffer[0],
  .stack_size = sizeof(chassisBuffer),
  .priority = (osPriority_t) osPriorityNormal,
};

void StartDefaultTask(void *argument);
void test_task(void *argument);
void remote_control_task(void *argument);
void decision_center_task(void *argument);
void safe_daemon_task(void *argument);
void imu_task(void *argument);
void chassis_task(void *argument);

extern void MX_USB_DEVICE_Init(void);
void MX_FREERTOS_Init(void); /* (MISRA C 2004 rule 8.1) */

void MX_FREERTOS_Init(void) {

  /* Create the thread(s) */
  /* creation of defaultTask */
  defaultTaskHandle = osThreadNew(StartDefaultTask, NULL, &defaultTask_attributes);

  /* creation of test */
  testHandle = osThreadNew(test_task, NULL, &test_attributes);

  /* creation of remote_control */
  remote_controlHandle = osThreadNew(remote_control_task, NULL, &remote_control_attributes);

  /* creation of decision_center */
  decision_centerHandle = osThreadNew(decision_center_task, NULL, &decision_center_attributes);

  /* creation of safe_daemon */
  safe_daemonHandle = osThreadNew(safe_daemon_task, NULL, &safe_daemon_attributes);

  /* creation of ins_task_rtos */
  ins_task_rtosHandle = osThreadNew(imu_task, NULL, &ins_task_rtos_attributes);

  /* creation of chassis */
  chassisHandle = osThreadNew(chassis_task, NULL, &chassis_attributes);

}

void StartDefaultTask(void *argument)
{
  /* init code for USB_DEVICE */
  MX_USB_DEVICE_Init();
  for(;;)
  {
    osDelay(1);
  }
}

__weak void test_task(void *argument)
{
  for(;;)
  {
    osDelay(1);
  }
}

__weak void remote_control_task(void *argument)
{
  for(;;)
  {
    osDelay(1);
  }
}

__weak void decision_center_task(void *argument)
{
  for(;;)
  {
    osDelay(1);
  }
}

__weak void safe_daemon_task(void *argument)
{
  for(;;)
  {
    osDelay(1);
  }
}

__weak void imu_task(void *argument)
{
  for(;;)
  {
    osDelay(1);
  }
}

__weak void chassis_task(void *argument)
{
  for(;;)
  {
    osDelay(1);
  }
}
